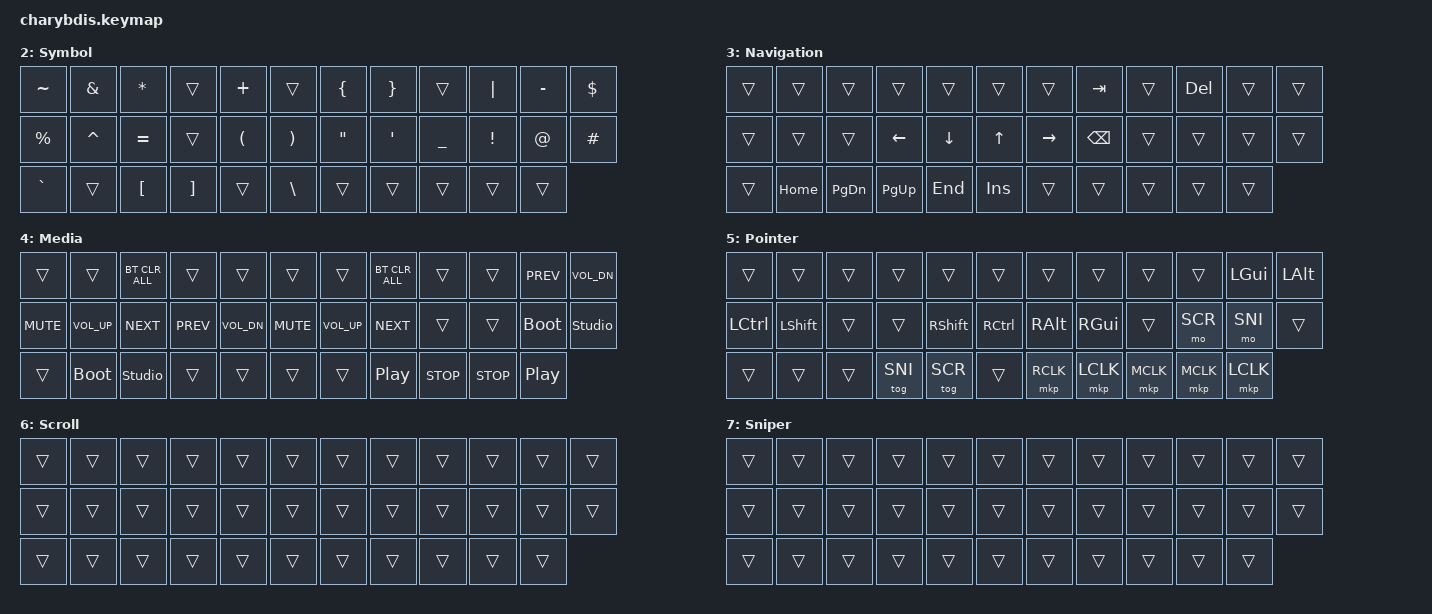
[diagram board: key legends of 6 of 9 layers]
#include <behaviors/mouse_keys.dtsi>
#include <dt-bindings/zmk/mouse.h>
#include <behaviors.dtsi>
#include <dt-bindings/zmk/bt.h>
#include <dt-bindings/zmk/keys.h>
#include <dt-bindings/zmk/outputs.h>
#include <dt-bindings/zmk/pointing.h>
#include <dt-bindings/zmk/rgb.h>

#define BASE 0
#define NUFU 1
#define SYM 2
#define NAV 3
#define MED 4
#define POI 5
#define SCR 6
#define SNI 7

&sl { release-after-ms = <250>; };

&mt {
    tapping-term-ms = <200>;
    require-prior-idle-ms = <150>;
};

/ {
    #include "combos.dtsi"

    behaviors {
        hml: homewrow_mods_left {
            compatible = "zmk,behavior-hold-tap";
            label = "HOMEROW_MODS_LEFT_HAND";
            bindings = <&kp>, <&kp>;

            #binding-cells = <2>;
            tapping-term-ms = <280>;
            hold-trigger-key-positions = <5 6 7 8 9 15 16 17 18 19 25 26 27 28 29 33 34>;
            flavor = "balanced";
            quick-tap-ms = <175>;
            require-prior-idle-ms = <125>;
            hold-trigger-on-release;
        };

        hmr: homewrow_mods_right {
            compatible = "zmk,behavior-hold-tap";
            label = "HOMEROW_MODS_RIGHT_HAND";
            bindings = <&kp>, <&kp>;

            #binding-cells = <2>;
            tapping-term-ms = <280>;
            hold-trigger-key-positions = <0 1 2 3 4 10 11 12 13 14 20 21 22 23 24 30 31 32>;
            flavor = "balanced";
            quick-tap-ms = <175>;
            require-prior-idle-ms = <125>;
            hold-trigger-on-release;
        };
    };

    macros {
        em_dash: em_dash {
            compatible = "zmk,behavior-macro";
            #binding-cells = <0>;
            bindings =
                <&em_dash>,
                <&macro_press>,
                <&kp LA(KP_NUMBER_0) &kp LA(KP_NUMBER_1) &kp LA(KP_NUMBER_5) &kp LA(KP_NUMBER_1)>,
                <&macro_press>;

            label = "EM_DASH";
        };

        en_dash: en_dash {
            compatible = "zmk,behavior-macro";
            #binding-cells = <0>;
            bindings =
                <&en_dash>,
                <&macro_press>,
                <&kp LA(KP_NUMBER_0) &kp LA(KP_NUMBER_1) &kp LA(KP_NUMBER_5) &kp LA(KP_NUMBER_0)>,
                <&macro_press>;

            label = "EN_DASH";
        };
    };

    keymap {
        compatible = "zmk,keymap";

        Base {
            label = "Base";
            bindings = <
&tog 1          &kp N1  &kp N2  &kp N3  &kp N4          &kp N5          &kp N6    &kp N7       &kp N8     &kp N9     &kp N0        &kp MINUS
&kp CAPS        &kp Q   &kp W   &kp E   &kp R           &kp T           &kp Y     &kp U        &kp I      &kp O      &kp P         &kp BSPC
&kp LEFT_SHIFT  &kp A   &kp S   &kp D   &kp F           &kp G           &kp H     &kp J        &kp K      &kp L      &kp SEMI      &kp APOS
&kp LCTRL       &kp Z   &kp X   &kp C   &kp V           &kp B           &kp N     &kp M        &kp COMMA  &lt 1 DOT  &kp QUESTION  &lt 1 DELETE
                                        &lt 4 LEFT_ALT  &kp LEFT_GUI    &kp UP    &kp LEFT     &kp RIGHT
                                                        &lt 1 ENTER     &kp DOWN  &lt 1 SPACE
            >;
        };

        NuFu {
            label = "Numeral/Function";
            bindings = <
&none            &none         &kp PLUS        &kp EQUAL     &kp LEFT_BRACE  &kp RIGHT_BRACE    &kp C_BRIGHTNESS_DEC  &kp C_BRIGHTNESS_INC  &kp PRINTSCREEN  &kp LEFT_BRACKET  &kp RIGHT_BRACKET  &em_dash
&kp TAB          &none         &kp LC(B)       &kp LC(I)     &kp LC(U)       &kp LA(LS(N5))     &kp KP_NUMBER_1       &kp KP_NUMBER_2       &kp KP_NUMBER_3  &kp KP_NUMBER_0   &kp PIPE           &en_dash
&rgb_ug RGB_TOG  &out OUT_TOG  &studio_unlock  &out OUT_TOG  &out OUT_TOG    &out OUT_TOG       &kp KP_NUMBER_4       &kp KP_NUMBER_5       &kp KP_NUMBER_6  &kp HOME          &kp BACKSLASH      &kp PAGE_UP
&bt BT_NXT       &bt BT_NXT    &bt BT_NXT      &bt BT_NXT    &bt BT_NXT      &kp SPACE          &kp KP_NUMBER_7       &kp KP_NUMBER_8       &kp KP_NUMBER_9  &kp END           &kp SLASH          &kp PAGE_DOWN
                                                             &kp BACKSPACE   &kp SPACE          &kp RIGHT_ALT         &kp ENTER             &kp RSHIFT
                                                                             &none              &none                 &none
            >;
        };

        Symbol {
            label = "Symbol";
            bindings = <
&kp TILDE  &kp AMPS   &kp STAR   &trans    &kp PLUS  &trans      &kp LBRC  &kp RBRC  &trans     &kp PIPE  &kp MINUS  &kp DLLR
&kp PRCNT  &kp CARET  &kp EQUAL  &trans    &kp LPAR  &kp RPAR    &kp DQT   &kp APOS  &kp UNDER  &kp EXCL  &kp AT     &kp HASH
&kp GRAVE  &trans     &kp LBKT   &kp RBKT  &trans    &kp BSLH    &trans    &trans    &trans     &trans    &trans
            >;
        };

        Navigation {
            label = "Navigation";
            bindings = <
&trans  &trans    &trans         &trans       &trans    &trans     &trans     &kp TAB        &trans  &kp DELETE  &trans  &trans
&trans  &trans    &trans         &kp LEFT     &kp DOWN  &kp UP     &kp RIGHT  &kp BACKSPACE  &trans  &trans      &trans  &trans
&trans  &kp HOME  &kp PAGE_DOWN  &kp PAGE_UP  &kp END   &kp INS    &trans     &trans         &trans  &trans      &trans
            >;
        };

        Media {
            label = "Media";
            bindings = <
&trans      &trans        &bt BT_CLR_ALL  &trans      &trans        &trans        &trans        &bt BT_CLR_ALL    &trans      &trans      &kp C_PREV        &kp C_VOL_DN
&kp C_MUTE  &kp C_VOL_UP  &kp C_NEXT      &kp C_PREV  &kp C_VOL_DN  &kp C_MUTE    &kp C_VOL_UP  &kp C_NEXT        &trans      &trans      &bootloader       &studio_unlock
&trans      &bootloader   &studio_unlock  &trans      &trans        &trans        &trans        &kp C_PLAY_PAUSE  &kp C_STOP  &kp C_STOP  &kp C_PLAY_PAUSE
            >;
        };

        Pointer {
            label = "Pointer";
            bindings = <
&trans     &trans     &trans  &trans    &trans     &trans       &trans     &trans     &trans     &trans     &kp LGUI   &kp LALT
&kp LCTRL  &kp LSHFT  &trans  &trans    &kp RSHFT  &kp RCTRL    &kp RALT   &kp RGUI   &trans     &mo SCR    &mo SNI    &trans
&trans     &trans     &trans  &tog SNI  &tog SCR   &trans       &mkp RCLK  &mkp LCLK  &mkp MCLK  &mkp MCLK  &mkp LCLK
            >;
        };

        Scroll {
            label = "Scroll";
            bindings = <
&trans  &trans  &trans  &trans  &trans  &trans    &trans  &trans  &trans  &trans  &trans  &trans
&trans  &trans  &trans  &trans  &trans  &trans    &trans  &trans  &trans  &trans  &trans  &trans
&trans  &trans  &trans  &trans  &trans  &trans    &trans  &trans  &trans  &trans  &trans
            >;
        };

        Sniper {
            label = "Sniper";
            bindings = <
&trans  &trans  &trans  &trans  &trans  &trans    &trans  &trans  &trans  &trans  &trans  &trans
&trans  &trans  &trans  &trans  &trans  &trans    &trans  &trans  &trans  &trans  &trans  &trans
&trans  &trans  &trans  &trans  &trans  &trans    &trans  &trans  &trans  &trans  &trans
            >;
        };

        layer_8 {
            bindings = <
&trans  &trans  &trans  &trans  &trans  &trans    &trans  &trans  &trans  &trans  &trans  &trans
&trans  &trans  &trans  &trans  &trans  &trans    &trans  &trans  &trans  &trans  &trans  &trans
&trans  &trans  &trans  &trans  &trans  &trans    &trans  &trans  &trans  &trans  &trans  &trans
&trans  &trans  &trans  &trans  &trans  &trans    &trans  &trans  &trans  &trans  &trans  &trans
                                &trans  &trans    &trans  &trans  &trans
                                        &trans    &trans  &trans
            >;
        };
    };
};
